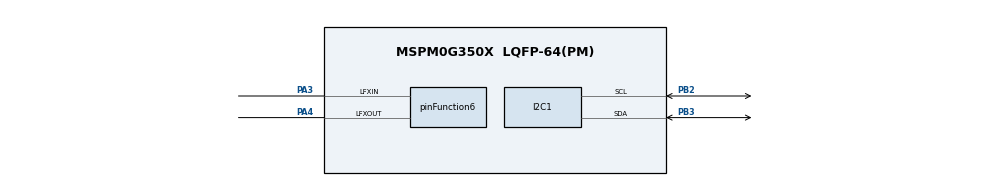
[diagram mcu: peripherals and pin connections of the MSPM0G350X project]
/**
 * @cliArgs --device "MSPM0G350X" --package "LQFP-64(PM)" --part "Default" --product "mspm0_sdk@0.52.00.03"
 * @versions {"tool":"1.15.0+2729"}
 */

/**
 * Import the modules used in this configuration.
 */
const Board  = scripting.addModule("/ti/driverlib/Board");
const GPIO   = scripting.addModule("/ti/driverlib/GPIO", {}, false);
const GPIO1  = GPIO.addInstance();
const I2C    = scripting.addModule("/ti/driverlib/I2C", {}, false);
const I2C1   = I2C.addInstance();
const RTC    = scripting.addModule("/ti/driverlib/RTC");
const SYSCTL = scripting.addModule("/ti/driverlib/SYSCTL");

/**
 * Write custom configuration values to the imported modules.
 */
const gate7  = system.clockTree["MFCLKGATE"];
gate7.enable = true;

const mux3       = system.clockTree["EXCLKMUX"];
mux3.inputSelect = "EXCLKMUX_LFCLK";

const mux5       = system.clockTree["EXLFMUX"];
mux5.inputSelect = "EXLFMUX_XTAL";

const mux9       = system.clockTree["LFXTMUX"];
mux9.inputSelect = "LFXTMUX_TRUE";

const pinFunction6                        = system.clockTree["LFXT"];
pinFunction6.inputFreq                    = 32.18;
pinFunction6.enable                       = true;
pinFunction6.LFCLKDriveStrength           = "HIGHER";
pinFunction6.peripheral.lfxInPin.$assign  = "PA3";
pinFunction6.peripheral.lfxOutPin.$assign = "PA4";

const monitor             = scripting.addModule("/ti/clockTree/monitor.js", {}, false);
const monitor1            = monitor.addInstance({}, false);
monitor1.$name            = "ti_clockTree_monitor0";
pinFunction6.LFCLKMonitor = monitor1;


GPIO1.$name                               = "GPIO_GRP_0";
GPIO1.associatedPins[0].$name             = "PIN_0";
GPIO1.associatedPins[0].launchPadShortcut = "LED1En";

I2C1.basicEnableTarget         = true;
I2C1.basicClockSourceDivider   = 8;
I2C1.$name                     = "I2C_target";
I2C1.intTarget                 = ["RXFIFO_TRIGGER","START","STOP","TXFIFO_TRIGGER"];
I2C1.peripheral.$assign        = "I2C1";
I2C1.peripheral.sdaPin.$assign = "PB3";
I2C1.peripheral.sclPin.$assign = "PB2";


SYSCTL.clockTreeEn = true;

/**
 * Pinmux solution for unlocked pins/peripherals. This ensures that minor changes to the automatic solver in a future
 * version of the tool will not impact the pinmux you originally saw.  These lines can be completely deleted in order to
 * re-solve from scratch.
 */
pinFunction6.peripheral.$suggestSolution     = "SYSCTL";
Board.peripheral.$suggestSolution            = "DEBUGSS";
Board.peripheral.swclkPin.$suggestSolution   = "PA20";
Board.peripheral.swdioPin.$suggestSolution   = "PA19";
GPIO1.associatedPins[0].pin.$suggestSolution = "PA0";
RTC.peripheral.$suggestSolution              = "RTC";
